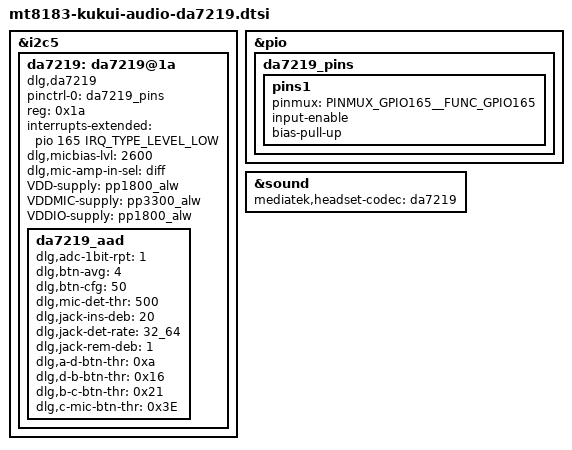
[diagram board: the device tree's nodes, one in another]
// SPDX-License-Identifier: (GPL-2.0 OR MIT)
/*
 * Google Kukui (and derivatives) audio fragment for da7219.
 *
 * Copyright 2020 Google LLC.
 */

&i2c5 {
	da7219: da7219@1a {
		pinctrl-names = "default";
		pinctrl-0 = <&da7219_pins>;
		compatible = "dlg,da7219";
		reg = <0x1a>;
		interrupts-extended = <&pio 165 IRQ_TYPE_LEVEL_LOW>;

		dlg,micbias-lvl = <2600>;
		dlg,mic-amp-in-sel = "diff";
		VDD-supply = <&pp1800_alw>;
		VDDMIC-supply = <&pp3300_alw>;
		VDDIO-supply = <&pp1800_alw>;

		status = "okay";

		da7219_aad {
			dlg,adc-1bit-rpt = <1>;
			dlg,btn-avg = <4>;
			dlg,btn-cfg = <50>;
			dlg,mic-det-thr = <500>;
			dlg,jack-ins-deb = <20>;
			dlg,jack-det-rate = "32_64";
			dlg,jack-rem-deb = <1>;

			dlg,a-d-btn-thr = <0xa>;
			dlg,d-b-btn-thr = <0x16>;
			dlg,b-c-btn-thr = <0x21>;
			dlg,c-mic-btn-thr = <0x3E>;
		};
	};
};

&pio {
	da7219_pins: da7219_pins {
		pins1 {
			pinmux = <PINMUX_GPIO165__FUNC_GPIO165>;
			input-enable;
			bias-pull-up;
		};
	};
};

&sound {
	mediatek,headset-codec = <&da7219>;
};
